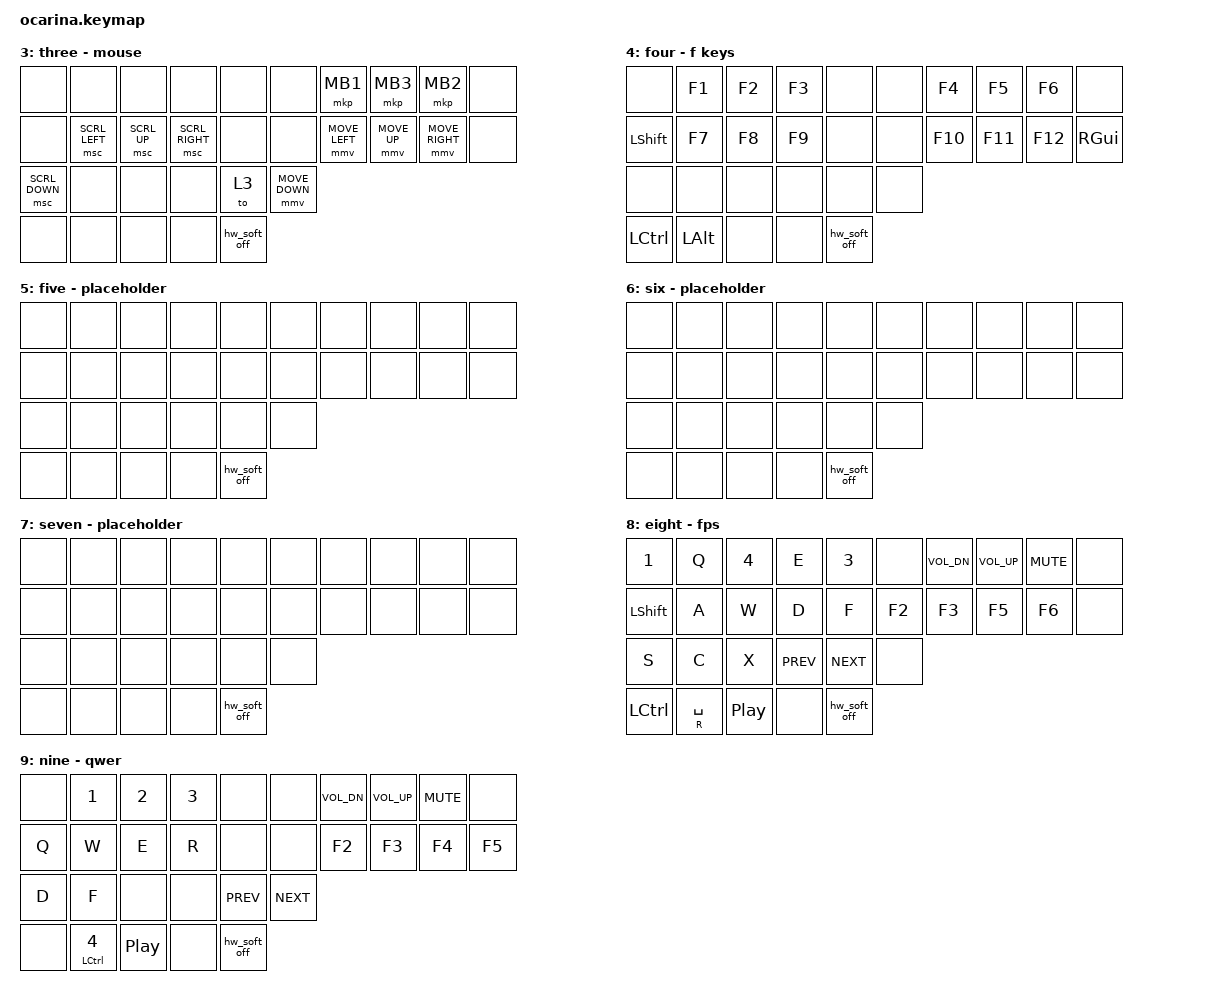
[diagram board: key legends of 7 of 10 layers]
#include "fingermap.h"

/ {
	behaviors {
		hml: home_row_mod_left {
            		hold-trigger-key-positions = <>; // List of keys on the right
        	};
        	hmr: home_row_mod_right {
            		hold-trigger-key-positions = <>; // List of keys on the left
        	};
		fhml: fast_home_row_mod_left {
            		hold-trigger-key-positions = <>; // List of keys on the right
        	};
        	fhmr: fast_home_row_mod_right {
            		hold-trigger-key-positions = <>; // List of keys on the left
        	};
	};
	keymap {
		compatible = "zmk,keymap";
		zero {
			display-name = "zero base";
			bindings = <
				LUP LUR LUM LUI LUN RUN RUI RUM RUR RUP
				LHP LHR	LHM LHI LHN RHN RHI RHM RHR RHP
					LBM LBI LBN RBN RBI RBM
					LN LH &none &none RH RN	
									&hw_soft_off
			>;
		};
		one { display-name = "one numbers icons";
			bindings = <
				LUP1 LUR1 LUM1 LUI1 LUN1 RUN1 RUI1 RUM1 RUR1 RUP1
				LHP1 LHR1 LHM1 LHI1 LHN1 RHN1 RHI1 RHM1 RHR1 RHP1
					  LBM1 LBI1 LBN1 RBN1 RBI1 RBM1
					   LN1 LH1 &none &none RH1 RN1	
									&hw_soft_off
			>;
		};
		two { display-name = "two navigation and kb functions";
			bindings = <
				LUP2 LUR2 LUM2 LUI2 LUN2 RUN2 RUI2 RUM2 RUR2 RUP2
				LHP2 LHR2 LHM2 LHI2 LHN2 RHN2 RHI2 RHM2 RHR2 RHP2
					  LBM2 LBI2 LBN2 RBN2 RBI2 RBM2
					   LN2 LH2 &none &none RH2 RN2	
									&hw_soft_off
			>;
		};
		three { display-name = "three - mouse";
			bindings = <
				&none &none &none &none &none &none &mkp MB1 &mkp MB3 &mkp MB2 &none
				&none &msc SCRL_LEFT &msc SCRL_UP &msc SCRL_RIGHT &none &none &mmv MOVE_LEFT &mmv MOVE_UP &mmv MOVE_RIGHT &none 
				&msc SCRL_DOWN &none &none &none &to 3 &mmv MOVE_DOWN
				&none &none &none &none &hw_soft_off
			>;
		};
		four { display-name = "four - f keys";
			bindings = <
				&none &kp F1 &kp F2 &kp F3 &none &none &kp F4 &kp F5 &kp F6 &none 
				&kp LSHIFT &kp F7 &kp F8 &kp F9 &none &none &kp F10 &kp F11 &kp F12 &kp RGUI 
				&none &none &none &none &none &none 
				&kp LCTRL &kp LALT &none &none &hw_soft_off
			>;
		};
		five { display-name = "five - placeholder";
			bindings = <
				&none &none &none &none &none &none &none &none &none &none
				&none &none &none &none &none &none &none &none &none &none
				&none &none &none &none &none &none 
				&none &none &none &none &hw_soft_off
			>;
		};
		six { display-name = "six - placeholder";
			bindings = <
				&none &none &none &none &none &none &none &none &none &none
				&none &none &none &none &none &none &none &none &none &none
				&none &none &none &none &none &none 
				&none &none &none &none &hw_soft_off
			>;
		};
		seven { display-name = "seven - placeholder";
			bindings = <
				&none &none &none &none &none &none &none &none &none &none
				&none &none &none &none &none &none &none &none &none &none
				&none &none &none &none &none &none 
				&none &none &none &none &hw_soft_off
			>;
		};
		eight { display-name = "eight - fps";
			bindings = <
				&kp N1 &kp Q &kp N4 &kp E &kp N3 &none &kp C_VOL_DN &kp C_VOL_UP &kp C_MUTE &none
				&kp LSHIFT &kp A &kp W &kp D &kp F &kp F2 &kp F3 &kp F5 &kp F6 &none
				&kp S &kp C &kp X &kp C_PREV &kp C_NEXT &none
				&kp LCTRL &mt R SPACE &kp C_PP &none &hw_soft_off
			>;
		};
		nine { display-name = "nine - qwer";
			bindings = <
				&none &kp N1 &kp N2 &kp N3 &none &none &kp C_VOL_DN &kp C_VOL_UP &kp C_MUTE &none
				&kp Q &kp W &kp E &kp R &none &none &kp F2 &kp F3 &kp F4 &kp F5
				&kp D &kp F &none &none &kp C_PREV &kp C_NEXT 
				&none &mt LCTRL N4 &kp C_PP &none &hw_soft_off
			>;
		};
	};
};

/ {
	combos {
		compatible = "zmk,combos";

// keyboard functions
		combo_bt_zero {
			timeout-ms = <50>;
			key-positions = <10 11 12 13>;
			bindings = <&bluetooth0>;
			layers = <0>;
		};
		combo_bt_one {
			timeout-ms = <50>;
			key-positions = <16 17 18 19>;
			bindings = <&bluetooth1>;
			layers = <0>;
		};
		combo_usb {
			timeout-ms = <50>;
			key-positions = <21 22 23 24>;
			bindings = <&out OUT_USB>;
			layers = <0>;
		};
		combo_fps_layer {
			timeout-ms = <50>;
			key-positions = <11 12 13>;
			bindings = <&to 8>;
			layers = <0>;
		};
		combo_qwer_layer {
			timeout-ms = <50>;
			key-positions = <10 11 13>;
			bindings = <&to 9>;
			layers = <0>;
		};
		combo_default_layer {
			timeout-ms = <50>;
			key-positions = <12 13 16 17>;
			bindings = <&to 0>;
		};
// mod keys
		combo_del {
			timeout-ms = <50>;
			key-positions = <10 11>;
			bindings = <&kp DEL>;
			layers = <0 1 2>;
		};
		combo_tab {
			timeout-ms = <50>;
			key-positions = <1 3>;
			bindings = <&kp TAB>;
		};
		combo_esc {
			timeout-ms = <50>;
			key-positions = <6 8>;
			bindings = <&kp ESC>;
		};
		combo_backspace {
			timeout-ms = <50>;
			key-positions = <18 19>;
			bindings = <&kp BSPC>;
			layers = <0 1 2>;
		};
		combo_enter {
			timeout-ms = <50>;
			key-positions = <13 16>;
			bindings = <&kp ENTER>;
			layers = <0 1 2>;
		};
		combo_capsword {
			timeout-ms = <50>;
			key-positions = <10 19>;
			bindings = <&caps_word>;
			layers = <0>;
		};
// arrow keys
		combo_up {
			timeout-ms = <50>;
			key-positions = <12 17>;
			bindings = <&kp UP>;
		};
		combo_left {
			timeout-ms = <50>;
			key-positions = <11 16>;
			bindings = <&kp LEFT>;
		};
		combo_down {
			timeout-ms = <50>;
			key-positions = <20 25>;
			bindings = <&kp DOWN>;
		};
		combo_right {
			timeout-ms = <50>;
			key-positions = <13 18>;
			bindings = <&kp RIGHT>;
		};
// game 
		combo_b_game {
			timeout-ms = <90>;
			key-positions = <20 21>;
			bindings = <&kp B>;
			layers = <8>;
		};
		combo_k_game {
			timeout-ms = <90>;
			key-positions = <10 27>;
			bindings = <&kp K>;
			layers = <8>;
		};
	};
};



